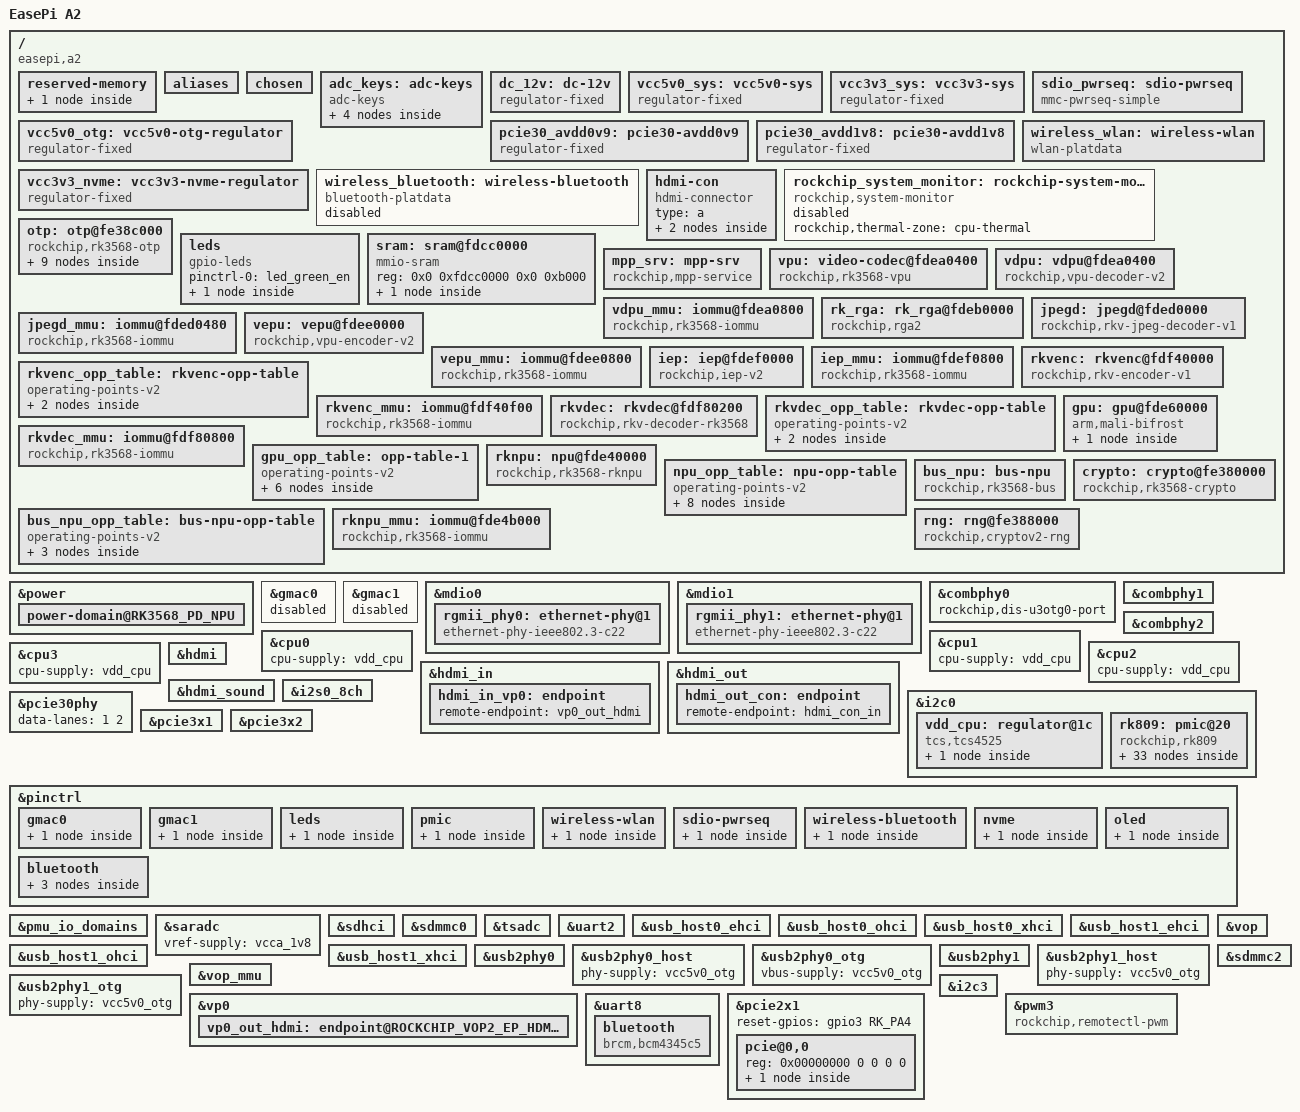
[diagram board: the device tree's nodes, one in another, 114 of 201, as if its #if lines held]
// SPDX-License-Identifier: GPL-2.0-or-later OR MIT
/*
 * Copyright (c) 2020 Rockchip Electronics Co., Ltd.
 * Copyright (c) 2021 Rockchip Electronics Co., Ltd.
 * Copyright (c) 2025 jjm2473 <jjm2473@gmail.com>
 */

/dts-v1/;
#include <dt-bindings/gpio/gpio.h>
#include <dt-bindings/input/input.h>
#include <dt-bindings/leds/common.h>
#include <dt-bindings/pinctrl/rockchip.h>
#include <dt-bindings/soc/rockchip,vop2.h>
#include "rk3568.dtsi"

/ {
	compatible = "easepi,a2", "rockchip,rk3568";
	model = "EasePi A2";
	kdebug = "0";
	hwmodel_id = "A2";
	hw_support = "hdmi";
	eth_order = "0000:01:00.0";

	reserved-memory {
		#address-cells = <2>;
		#size-cells = <2>;
		ranges;

		ramoops: ramoops@110000 {
			compatible = "ramoops";
			reg = <0 0x110000 0 0xf0000>;
			console-size = <0x80000>;
			ftrace-size = <0x00000>;
			pmsg-size = <0x50000>;
			record-size = <0x20000>;
		};
	};

	aliases {
		mmc0 = &sdmmc0;
		mmc1 = &sdhci;
		mmc2 = &sdmmc2;

		ethernet0 = &pcie_eth0;

		serial0 = &uart8;

		led-boot = &led_green;
		led-failsafe = &led_green;
		led-running = &led_green;
		led-upgrade = &led_green;
	};

	chosen {
		stdout-path = "serial2:1500000n8";
		power-key-factory-reset;
		power-key-dbclick;
	};

	adc_keys: adc-keys {
		compatible = "adc-keys";
		io-channels = <&saradc 0>;
		io-channel-names = "buttons";
		keyup-threshold-microvolt = <1800000>;
		poll-interval = <100>;

		vol-up-key {
		label = "volume up";
		linux,code = <KEY_VOLUMEUP>;
		press-threshold-microvolt = <175000>;
	};

		vol-down-key {
			label = "volume down";
			linux,code = <KEY_VOLUMEDOWN>;
			press-threshold-microvolt = <297500>;
		};

		menu-key {
			label = "menu";
			linux,code = <KEY_MENU>;
			press-threshold-microvolt = <980000>;
		};

		back-key {
			label = "back";
			linux,code = <KEY_BACK>;
			press-threshold-microvolt = <1305500>;
		};
	};

	dc_12v: dc-12v {
		compatible = "regulator-fixed";
		regulator-name = "dc_12v";
		regulator-always-on;
		regulator-boot-on;
		regulator-min-microvolt = <12000000>;
		regulator-max-microvolt = <12000000>;
	};
	vcc5v0_sys: vcc5v0-sys {
		compatible = "regulator-fixed";
		regulator-name = "vcc5v0_sys";
		regulator-always-on;
		regulator-boot-on;
		regulator-min-microvolt = <5000000>;
		regulator-max-microvolt = <5000000>;
		vin-supply = <&dc_12v>;
	};
	vcc3v3_sys: vcc3v3-sys {
		compatible = "regulator-fixed";
		regulator-name = "vcc3v3_sys";
		regulator-always-on;
		regulator-boot-on;
		regulator-min-microvolt = <3300000>;
		regulator-max-microvolt = <3300000>;
		vin-supply = <&dc_12v>;
	};
	vcc5v0_otg: vcc5v0-otg-regulator {
		compatible = "regulator-fixed";
		regulator-name = "vcc5v0_otg";
		regulator-always-on;
		regulator-boot-on;
		regulator-min-microvolt = <5000000>;
		regulator-max-microvolt = <5000000>;
		vin-supply = <&vcc5v0_sys>;
	};
	pcie30_avdd0v9: pcie30-avdd0v9 {
		compatible = "regulator-fixed";
		regulator-name = "pcie30_avdd0v9";
		regulator-always-on;
		regulator-boot-on;
		regulator-min-microvolt = <900000>;
		regulator-max-microvolt = <900000>;
		vin-supply = <&vcc3v3_sys>;
	};
	pcie30_avdd1v8: pcie30-avdd1v8 {
		compatible = "regulator-fixed";
		regulator-name = "pcie30_avdd1v8";
		regulator-always-on;
		regulator-boot-on;
		regulator-min-microvolt = <1800000>;
		regulator-max-microvolt = <1800000>;
		vin-supply = <&vcc3v3_sys>;
	};
	vcc3v3_nvme: vcc3v3-nvme-regulator {
		compatible = "regulator-fixed";
		regulator-name = "vcc3v3_nvme";
		regulator-min-microvolt = <3300000>;
		regulator-max-microvolt = <3300000>;
		enable-active-high;
		gpio = <&gpio0 RK_PA5 GPIO_ACTIVE_HIGH>;
		vin-supply = <&dc_12v>;
		pinctrl-names = "default";
		pinctrl-0 = <&vcc3v3_nvme_en>;
	};

	sdio_pwrseq: sdio-pwrseq {
		compatible = "mmc-pwrseq-simple";
		clocks = <&rk809 1>;
		clock-names = "ext_clock";
		pinctrl-names = "default";
		pinctrl-0 = <&wifi_enable_h>;
	};

	wireless_wlan: wireless-wlan {
		compatible = "wlan-platdata";
		rockchip,grf = <&grf>;
		wifi_chip_type = "ap6398s";
		WIFI,poweren_gpio = <&gpio3 RK_PD5 GPIO_ACTIVE_HIGH>;
		status = "okay";
	};

	wireless_bluetooth: wireless-bluetooth {
		compatible = "bluetooth-platdata";
		clocks = <&rk809 1>;
		clock-names = "ext_clock";
		uart_rts_gpios = <&gpio2 RK_PB1 GPIO_ACTIVE_LOW>;
		pinctrl-names = "default", "rts_gpio";
		pinctrl-0 = <&uart8m0_rtsn>;
		pinctrl-1 = <&uart8_gpios>;
		BT,reset_gpio    = <&gpio3 RK_PA0 GPIO_ACTIVE_HIGH>;
		BT,wake_gpio     = <&gpio3 RK_PA1 GPIO_ACTIVE_HIGH>;
		BT,wake_host_irq = <&gpio3 RK_PA2 GPIO_ACTIVE_HIGH>;
		status = "okay";
	};

	hdmi-con {
		compatible = "hdmi-connector";
		type = "a";

		port {
			hdmi_con_in: endpoint {
				remote-endpoint = <&hdmi_out_con>;
			};
		};
	};

	rockchip_system_monitor: rockchip-system-monitor {
		compatible = "rockchip,system-monitor";
		rockchip,thermal-zone = "cpu-thermal";
		status = "disabled";
	};

	otp: otp@fe38c000 {
		compatible = "rockchip,rk3568-otp";
		reg = <0x0 0xfe38c000 0x0 0x4000>;
		#address-cells = <1>;
		#size-cells = <1>;
		clocks = <&cru CLK_OTPC_NS_USR>, <&cru CLK_OTPC_NS_SBPI>,
				<&cru PCLK_OTPC_NS>, <&cru PCLK_OTPPHY>;
		clock-names = "usr", "sbpi", "apb", "phy";
		resets = <&cru SRST_OTPPHY>;
		reset-names = "otp_phy";

		specification_serial_number: specification-serial-number@7 {
			reg = <0x07 0x1>;
			bits = <0 5>;
		};
		mbist_vmin: mbist-vmin@9 {
			reg = <0x09 0x1>;
			bits = <0 4>;
		};
		log_leakage: log-leakage@1b {
			reg = <0x1b 0x1>;
		};
		core_pvtm: core-pvtm@2a {
			reg = <0x2a 0x2>;
		};
		remark_spec_serial_number: remark-spec-serial-number@56 {
			reg = <0x56 0x1>;
			bits = <0 5>;
		};
	};

	leds {
		compatible = "gpio-leds";
		pinctrl-names = "default";
		pinctrl-0 = <&led_green_en>;

		led_green: green {
			gpios = <&gpio2 RK_PD7 GPIO_ACTIVE_HIGH>;
			label = "green:sys";
			linux,default-trigger = "timer";
		};
	};

};

/* ===== Inline VPU support (from rk3568-vpu.dtsi) ===== */
/delete-node/ &vepu;

/ {
	sram: sram@fdcc0000 {
		compatible = "mmio-sram";
		reg = <0x0 0xfdcc0000 0x0 0xb000>;

		#address-cells = <1>;
		#size-cells = <1>;
		ranges = <0x0 0x0 0xfdcc0000 0xb000>;

		/* start address and size should be 4k algin */
		rkvdec_sram: rkvdec-sram@0 {
			reg = <0x0 0xb000>;
		};
	};

	mpp_srv: mpp-srv {
		compatible = "rockchip,mpp-service";
		rockchip,taskqueue-count = <6>;
		rockchip,resetgroup-count = <6>;
		status = "disabled";
	};

	vpu: video-codec@fdea0400 {
		compatible = "rockchip,rk3568-vpu";
		reg = <0x0 0xfdea0000 0x0 0x800>;
		interrupts = <GIC_SPI 139 IRQ_TYPE_LEVEL_HIGH>;
		clocks = <&cru ACLK_VPU>, <&cru HCLK_VPU>;
		clock-names = "aclk", "hclk";
		iommus = <&vdpu_mmu>;
		power-domains = <&power RK3568_PD_VPU>;
	};

	vdpu: vdpu@fdea0400 {
		compatible = "rockchip,vpu-decoder-v2";
		reg = <0x0 0xfdea0400 0x0 0x400>;
		interrupts = <GIC_SPI 139 IRQ_TYPE_LEVEL_HIGH>;
		interrupt-names = "irq_dec";
		clocks = <&cru ACLK_VPU>, <&cru HCLK_VPU>;
		clock-names = "aclk_vcodec", "hclk_vcodec";
		resets = <&cru SRST_A_VPU>, <&cru SRST_H_VPU>;
		reset-names = "video_a", "video_h";
		iommus = <&vdpu_mmu>;
		power-domains = <&power RK3568_PD_VPU>;
		rockchip,srv = <&mpp_srv>;
		rockchip,taskqueue-node = <0>;
		rockchip,resetgroup-node = <0>;
		status = "disabled";
	};

	vdpu_mmu: iommu@fdea0800 {
		compatible = "rockchip,rk3568-iommu", "rockchip,iommu-v2";
		reg = <0x0 0xfdea0800 0x0 0x40>;
		interrupts = <GIC_SPI 138 IRQ_TYPE_LEVEL_HIGH>;
		interrupt-names = "vdpu_mmu";
		clock-names = "aclk", "iface";
		clocks = <&cru ACLK_VPU>, <&cru HCLK_VPU>;
		power-domains = <&power RK3568_PD_VPU>;
		#iommu-cells = <0>;
		status = "disabled";
	};

	rk_rga: rk_rga@fdeb0000 {
		compatible = "rockchip,rga2";
		reg = <0x0 0xfdeb0000 0x0 0x1000>;
		interrupts = <GIC_SPI 90 IRQ_TYPE_LEVEL_HIGH>;
		clocks = <&cru ACLK_RGA>, <&cru HCLK_RGA>, <&cru CLK_RGA_CORE>;
		clock-names = "aclk_rga", "hclk_rga", "clk_rga";
		power-domains = <&power RK3568_PD_RGA>;
		status = "disabled";
	};

	jpegd: jpegd@fded0000 {
		compatible = "rockchip,rkv-jpeg-decoder-v1";
		reg = <0x0 0xfded0000 0x0 0x400>;
		interrupts = <GIC_SPI 62 IRQ_TYPE_LEVEL_HIGH>;
		clocks = <&cru ACLK_JDEC>, <&cru HCLK_JDEC>;
		clock-names = "aclk_vcodec", "hclk_vcodec";
		rockchip,disable-auto-freq;
		resets = <&cru SRST_A_JDEC>, <&cru SRST_H_JDEC>;
		reset-names = "video_a", "video_h";
		iommus = <&jpegd_mmu>;
		rockchip,srv = <&mpp_srv>;
		rockchip,taskqueue-node = <1>;
		rockchip,resetgroup-node = <1>;
		power-domains = <&power RK3568_PD_RGA>;
		status = "disabled";
	};

	jpegd_mmu: iommu@fded0480 {
		compatible = "rockchip,rk3568-iommu", "rockchip,iommu-v2";
		reg = <0x0 0xfded0480 0x0 0x40>;
		interrupts = <GIC_SPI 61 IRQ_TYPE_LEVEL_HIGH>;
		interrupt-names = "jpegd_mmu";
		clock-names = "aclk", "iface";
		clocks = <&cru ACLK_JDEC>, <&cru HCLK_JDEC>;
		power-domains = <&power RK3568_PD_RGA>;
		#iommu-cells = <0>;
		status = "disabled";
	};

	vepu: vepu@fdee0000 {
		compatible = "rockchip,vpu-encoder-v2";
		reg = <0x0 0xfdee0000 0x0 0x400>;
		interrupts = <GIC_SPI 64 IRQ_TYPE_LEVEL_HIGH>;
		clocks = <&cru ACLK_JENC>, <&cru HCLK_JENC>;
		clock-names = "aclk_vcodec", "hclk_vcodec";
		rockchip,disable-auto-freq;
		resets = <&cru SRST_A_JENC>, <&cru SRST_H_JENC>;
		reset-names = "video_a", "video_h";
		iommus = <&vepu_mmu>;
		rockchip,srv = <&mpp_srv>;
		rockchip,taskqueue-node = <2>;
		rockchip,resetgroup-node = <2>;
		power-domains = <&power RK3568_PD_RGA>;
		status = "disabled";
	};

	vepu_mmu: iommu@fdee0800 {
		compatible = "rockchip,rk3568-iommu", "rockchip,iommu-v2";
		reg = <0x0 0xfdee0800 0x0 0x40>;
		interrupts = <GIC_SPI 63 IRQ_TYPE_LEVEL_HIGH>;
		interrupt-names = "vepu_mmu";
		clocks = <&cru ACLK_JENC>, <&cru HCLK_JENC>;
		clock-names = "aclk", "iface";
		power-domains = <&power RK3568_PD_RGA>;
		#iommu-cells = <0>;
		status = "disabled";
	};

	iep: iep@fdef0000 {
		compatible = "rockchip,iep-v2";
		reg = <0x0 0xfdef0000 0x0 0x500>;
		interrupts = <GIC_SPI 56 IRQ_TYPE_LEVEL_HIGH>;
		clocks = <&cru ACLK_IEP>, <&cru HCLK_IEP>, <&cru CLK_IEP_CORE>;
		clock-names = "aclk", "hclk", "sclk";
		resets = <&cru SRST_A_IEP>, <&cru SRST_H_IEP>,
			<&cru SRST_IEP_CORE>;
		reset-names = "rst_a", "rst_h", "rst_s";
		power-domains = <&power RK3568_PD_RGA>;
		rockchip,srv = <&mpp_srv>;
		rockchip,taskqueue-node = <5>;
		rockchip,resetgroup-node = <5>;
		iommus = <&iep_mmu>;
		status = "disabled";
	};

	iep_mmu: iommu@fdef0800 {
		compatible = "rockchip,rk3568-iommu", "rockchip,iommu-v2";
		reg = <0x0 0xfdef0800 0x0 0x100>;
		interrupts = <GIC_SPI 56 IRQ_TYPE_LEVEL_HIGH>;
		interrupt-names = "iep_mmu";
		clocks = <&cru ACLK_IEP>, <&cru HCLK_IEP>;
		clock-names = "aclk", "iface";
		#iommu-cells = <0>;
		power-domains = <&power RK3568_PD_RGA>;
		status = "disabled";
	};

	rkvenc: rkvenc@fdf40000 {
		compatible = "rockchip,rkv-encoder-v1";
		reg = <0x0 0xfdf40000 0x0 0x400>;
		interrupts = <GIC_SPI 140 IRQ_TYPE_LEVEL_HIGH>;
		interrupt-names = "irq_enc";
		clocks = <&cru ACLK_RKVENC>, <&cru HCLK_RKVENC>,
			<&cru CLK_RKVENC_CORE>;
		clock-names = "aclk_vcodec", "hclk_vcodec", "clk_core";
		rockchip,normal-rates = <297000000>, <0>, <297000000>;
		resets = <&cru SRST_A_RKVENC>, <&cru SRST_H_RKVENC>,
			<&cru SRST_RKVENC_CORE>;
		reset-names = "video_a", "video_h", "video_core";
		assigned-clocks = <&cru ACLK_RKVENC>, <&cru CLK_RKVENC_CORE>;
		assigned-clock-rates = <297000000>, <297000000>;
		iommus = <&rkvenc_mmu>;
		node-name = "rkvenc";
		rockchip,srv = <&mpp_srv>;
		rockchip,taskqueue-node = <3>;
		rockchip,resetgroup-node = <3>;
		power-domains = <&power RK3568_PD_RKVENC>;
		status = "disabled";
	};

	rkvenc_opp_table: rkvenc-opp-table {
		compatible = "operating-points-v2";

		nvmem-cells = <&core_pvtm>;
		nvmem-cell-names = "pvtm";
		rockchip,pvtm-voltage-sel = <
			0        84000   0
			84001    91000   1
			91001    100000  2
		>;
		rockchip,pvtm-ch = <0 5>;

		opp-297000000 {
			opp-hz = /bits/ 64 <297000000>;
			opp-microvolt = <900000>;
			opp-microvolt-L0 = <900000>;
			opp-microvolt-L1 = <875000>;
			opp-microvolt-L2 = <875000>;
		};
		opp-400000000 {
			opp-hz = /bits/ 64 <400000000>;
			opp-microvolt = <950000>;
			opp-microvolt-L0 = <950000>;
			opp-microvolt-L1 = <925000>;
			opp-microvolt-L2 = <900000>;
		};
	};

	rkvenc_mmu: iommu@fdf40f00 {
		compatible = "rockchip,rk3568-iommu", "rockchip,iommu-v2";
		reg = <0x0 0xfdf40f00 0x0 0x40>, <0x0 0xfdf40f40 0x0 0x40>;
		interrupts = <GIC_SPI 141 IRQ_TYPE_LEVEL_HIGH>,
			<GIC_SPI 142 IRQ_TYPE_LEVEL_HIGH>;
		interrupt-names = "rkvenc_mmu0", "rkvenc_mmu1";
		clocks = <&cru ACLK_RKVENC>, <&cru HCLK_RKVENC>;
		clock-names = "aclk", "iface";
		rockchip,disable-mmu-reset;
		rockchip,enable-cmd-retry;
		#iommu-cells = <0>;
		power-domains = <&power RK3568_PD_RKVENC>;
		status = "disabled";
	};

	rkvdec: rkvdec@fdf80200 {
		compatible = "rockchip,rkv-decoder-rk3568", "rockchip,rkv-decoder-v2";
		reg = <0x0 0xfdf80200 0x0 0x400>, <0x0 0xfdf80100 0x0 0x100>;
		reg-names = "regs", "link";
		interrupts = <GIC_SPI 91 IRQ_TYPE_LEVEL_HIGH>;
		interrupt-names = "irq_dec";
		clocks = <&cru ACLK_RKVDEC>, <&cru HCLK_RKVDEC>,
			 <&cru CLK_RKVDEC_CA>, <&cru CLK_RKVDEC_CORE>,
			 <&cru CLK_RKVDEC_HEVC_CA>;
		clock-names = "aclk_vcodec", "hclk_vcodec","clk_cabac",
			      "clk_core", "clk_hevc_cabac";
		rockchip,normal-rates = <297000000>, <0>, <297000000>,
					<297000000>, <600000000>;
		rockchip,advanced-rates = <396000000>, <0>, <396000000>,
					<396000000>, <600000000>;
		rockchip,default-max-load = <2088960>;
		resets = <&cru SRST_A_RKVDEC>, <&cru SRST_H_RKVDEC>,
			 <&cru SRST_RKVDEC_CA>, <&cru SRST_RKVDEC_CORE>,
			 <&cru SRST_RKVDEC_HEVC_CA>;
		assigned-clocks = <&cru ACLK_RKVDEC>, <&cru CLK_RKVDEC_CA>,
				  <&cru CLK_RKVDEC_CORE>, <&cru CLK_RKVDEC_HEVC_CA>;
		assigned-clock-rates = <297000000>, <297000000>, <297000000>, <297000000>;
		reset-names = "video_a", "video_h", "video_cabac",
			      "video_core", "video_hevc_cabac";
		power-domains = <&power RK3568_PD_RKVDEC>;
		vdec-supply = <&vdd_logic>;
		iommus = <&rkvdec_mmu>;
		rockchip,srv = <&mpp_srv>;
		rockchip,taskqueue-node = <4>;
		rockchip,resetgroup-node = <4>;
		rockchip,sram = <&rkvdec_sram>;
		/* rcb_iova: start and size */
		rockchip,rcb-iova = <0x10000000 65536>;
		rockchip,rcb-min-width = <512>;
		rockchip,task-capacity = <16>;
		status = "disabled";
	};

	rkvdec_opp_table: rkvdec-opp-table {
		compatible = "operating-points-v2";

		nvmem-cells = <&log_leakage>, <&core_pvtm>;
		nvmem-cell-names = "leakage", "pvtm";
		rockchip,leakage-voltage-sel = <
			1   80    0
			81  254   1
		>;
		rockchip,pvtm-voltage-sel = <
			0        84000   0
			84001    100000  1
		>;
		rockchip,pvtm-ch = <0 5>;

		opp-297000000 {
			opp-hz = /bits/ 64 <297000000>;
			opp-microvolt = <900000>;
			opp-microvolt-L0 = <900000>;
			opp-microvolt-L1 = <875000>;
		};
		opp-400000000 {
			opp-hz = /bits/ 64 <400000000>;
			opp-microvolt = <900000>;
		};
	};

	rkvdec_mmu: iommu@fdf80800 {
		compatible = "rockchip,rk3568-iommu", "rockchip,iommu-v2";
		reg = <0x0 0xfdf80800 0x0 0x40>, <0x0 0xfdf80840 0x0 0x40>;
		interrupts = <GIC_SPI 92 IRQ_TYPE_LEVEL_HIGH>;
		interrupt-names = "rkvdec_mmu";
		clocks = <&cru ACLK_RKVDEC>, <&cru HCLK_RKVDEC>;
		clock-names = "aclk", "iface";
		power-domains = <&power RK3568_PD_RKVDEC>;
		#iommu-cells = <0>;
		status = "disabled";
	};

};

&iep {
	status = "okay";
};

&iep_mmu {
	status = "okay";
};

&jpegd {
	status = "okay";
};

&jpegd_mmu {
	status = "okay";
};

&mpp_srv {
	status = "okay";
};

&rk_rga {
	status = "okay";
};

&rkvdec {
	rockchip,disable-auto-freq;
	assigned-clock-rates = <396000000>, <396000000>, <396000000>, <600000000>;
	status = "okay";
};

&rkvdec_mmu {
	status = "okay";
};

&rkvenc {
	status = "okay";
};

&rkvenc_mmu {
	status = "okay";
};

&vdpu {
	status = "okay";
};

&vdpu_mmu {
	status = "okay";
};

&vepu {
	status = "okay";
};

&vepu_mmu {
	status = "okay";
};

/* ===== Inline GPU support (from rk3568-gpu.dtsi) ===== */
&otp {
	gpu_leakage: gpu-leakage@1d {
		reg = <0x1d 0x1>;
	};
	gpu_opp_info: gpu-opp-info@3c {
		reg = <0x3c 0x6>;
	};
};

/ {

	gpu_opp_table: opp-table-1 {
		compatible = "operating-points-v2";

		mbist-vmin = <825000 900000 950000>;
		nvmem-cells = <&gpu_leakage>, <&core_pvtm>, <&mbist_vmin>, <&gpu_opp_info>,
			      <&specification_serial_number>, <&remark_spec_serial_number>;
		nvmem-cell-names = "leakage", "pvtm", "mbist-vmin", "opp-info",
				   "specification_serial_number", "remark_spec_serial_number";
		rockchip,supported-hw;
		rockchip,max-volt = <1000000>;
		rockchip,temp-hysteresis = <5000>;
		rockchip,low-temp = <0>;
		rockchip,low-temp-adjust-volt = <
			/* MHz    MHz    uV */
			   0      800    50000
		>;
		rockchip,pvtm-voltage-sel = <
			0        84000   0
			84001    87000   1
			87001    91000   2
			91001    100000  3
		>;
		rockchip,pvtm-ch = <0 5>;

		/* RK3568 && RK3568M gpu OPPs */
		opp-200000000 {
			opp-supported-hw = <0xfb 0xffff>;
			opp-hz = /bits/ 64 <200000000>;
			opp-microvolt = <850000 850000 1000000>;
		};

		opp-300000000 {
			opp-supported-hw = <0xfb 0xffff>;
			opp-hz = /bits/ 64 <300000000>;
			opp-microvolt = <850000 850000 1000000>;
		};

		opp-400000000 {
			opp-supported-hw = <0xfb 0xffff>;
			opp-hz = /bits/ 64 <400000000>;
			opp-microvolt = <850000 850000 1000000>;
		};

		opp-600000000 {
			opp-supported-hw = <0xfb 0xffff>;
			opp-hz = /bits/ 64 <600000000>;
			opp-microvolt = <900000 900000 1000000>;
			opp-microvolt-L0 = <900000 900000 1000000>;
			opp-microvolt-L1 = <875000 875000 1000000>;
			opp-microvolt-L2 = <850000 850000 1000000>;
			opp-microvolt-L3 = <850000 850000 1000000>;
		};

		opp-700000000 {
			opp-supported-hw = <0xfb 0xffff>;
			opp-hz = /bits/ 64 <700000000>;
			opp-microvolt = <950000 950000 1000000>;
			opp-microvolt-L0 = <950000 950000 1000000>;
			opp-microvolt-L1 = <925000 925000 1000000>;
			opp-microvolt-L2 = <900000 900000 1000000>;
			opp-microvolt-L3 = <875000 875000 1000000>;
		};

		opp-800000000 {
			opp-supported-hw = <0xf9 0xffff>;
			opp-hz = /bits/ 64 <800000000>;
			opp-microvolt = <1000000 1000000 1000000>;
			opp-microvolt-L0 = <1000000 1000000 1000000>;
			opp-microvolt-L1 = <975000 975000 1000000>;
			opp-microvolt-L2 = <950000 950000 1000000>;
			opp-microvolt-L3 = <925000 925000 1000000>;
		};
	};

	gpu: gpu@fde60000 {
		compatible = "arm,mali-bifrost";
		reg = <0x0 0xfde60000 0x0 0x4000>;

		interrupts = <GIC_SPI 39 IRQ_TYPE_LEVEL_HIGH>,
			     <GIC_SPI 41 IRQ_TYPE_LEVEL_HIGH>,
			     <GIC_SPI 40 IRQ_TYPE_LEVEL_HIGH>;
		interrupt-names = "gpu", "mmu", "job";

		upthreshold = <40>;
		downdifferential = <10>;

		clocks = <&scmi_clk 1>, <&cru CLK_GPU>;
		clock-names = "gpu", "bus";
		power-domains = <&power RK3568_PD_GPU>;
		#cooling-cells = <2>;
		operating-points-v2 = <&gpu_opp_table>;

		status = "disabled";
		gpu_power_model: power-model {
			compatible = "simple-power-model";
			leakage-range= <5 15>;
			ls = <(-24002) 22823 0>;
			static-coefficient = <100000>;
			dynamic-coefficient = <953>;
			ts = <(-108890) 63610 (-1355) 20>;
			thermal-zone = "gpu-thermal";
		};
	};

};

/* ===== Inline NPU support (from rk3568-npu.dtsi) ===== */
&otp {
	npu_leakage: npu-leakage@1c {
		reg = <0x1c 0x1>;
	};
	npu_opp_info: npu-opp-info@42 {
		reg = <0x42 0x6>;
	};
};

&power {
	// vcc-supply = <&vdd_npu>;
	// These power domains are grouped by VD_NPU
	power-domain@RK3568_PD_NPU {
		reg = <RK3568_PD_NPU>;
		clocks = <&cru ACLK_NPU_PRE>,
				<&cru HCLK_NPU_PRE>,
				<&cru PCLK_NPU_PRE>;
		pm_qos = <&qos_npu>;
		#power-domain-cells = <0>;
	};
};

/ {

	rknpu: npu@fde40000 {
		compatible = "rockchip,rk3568-rknpu", "rockchip,rknpu";
		reg = <0x0 0xfde40000 0x0 0x10000>;
		interrupts = <GIC_SPI 151 IRQ_TYPE_LEVEL_HIGH>;
		clocks = <&scmi_clk 2>, <&cru CLK_NPU>, <&cru ACLK_NPU>, <&cru HCLK_NPU>;
		clock-names = "scmi_clk", "clk", "aclk", "hclk";
		assigned-clocks = <&cru CLK_NPU>;
		assigned-clock-rates = <600000000>;
		resets = <&cru SRST_A_NPU>, <&cru SRST_H_NPU>;
		reset-names = "srst_a", "srst_h";
		power-domains = <&power RK3568_PD_NPU>;
		operating-points-v2 = <&npu_opp_table>;
		iommus = <&rknpu_mmu>;
		status = "disabled";
	};

	npu_opp_table: npu-opp-table {
		compatible = "operating-points-v2";

		mbist-vmin = <825000 900000 950000>;
		nvmem-cells = <&npu_leakage>, <&core_pvtm>, <&mbist_vmin>, <&npu_opp_info>,
			      <&specification_serial_number>, <&remark_spec_serial_number>;
		nvmem-cell-names = "leakage", "pvtm", "mbist-vmin", "opp-info",
				   "specification_serial_number", "remark_spec_serial_number";
		rockchip,supported-hw;
		rockchip,max-volt = <1000000>;
		rockchip,temp-hysteresis = <5000>;
		rockchip,low-temp = <0>;
		rockchip,low-temp-adjust-volt = <
			/* MHz    MHz    uV */
			   0      1000    50000
		>;
		rockchip,pvtm-voltage-sel = <
			0        84000   0
			84001    87000   1
			87001    91000   2
			91001    100000  3
		>;
		rockchip,pvtm-ch = <0 5>;
		rockchip,init-freq = <900000>;

		/* RK3568 && RK3568M npu OPPs */
		opp-200000000 {
			opp-supported-hw = <0xfb 0xffff>;
			opp-hz = /bits/ 64 <200000000>;
			opp-microvolt = <850000 850000 1000000>;
		};
		opp-300000000 {
			opp-supported-hw = <0xfb 0xffff>;
			opp-hz = /bits/ 64 <297000000>;
			opp-microvolt = <850000 850000 1000000>;
		};
		opp-400000000 {
			opp-supported-hw = <0xfb 0xffff>;
			opp-hz = /bits/ 64 <400000000>;
			opp-microvolt = <850000 850000 1000000>;
		};
		opp-600000000 {
			opp-supported-hw = <0xfb 0xffff>;
			opp-hz = /bits/ 64 <600000000>;
			opp-microvolt = <850000 850000 1000000>;
		};
		opp-700000000 {
			opp-supported-hw = <0xfb 0xffff>;
			opp-hz = /bits/ 64 <700000000>;
			opp-microvolt = <875000 875000 1000000>;
			opp-microvolt-L0 = <875000 875000 1000000>;
			opp-microvolt-L1 = <850000 850000 1000000>;
			opp-microvolt-L2 = <850000 850000 1000000>;
			opp-microvolt-L3 = <850000 850000 1000000>;
		};
		opp-800000000 {
			opp-supported-hw = <0xfb 0xffff>;
			opp-hz = /bits/ 64 <800000000>;
			opp-microvolt = <925000 925000 1000000>;
			opp-microvolt-L0 = <925000 925000 1000000>;
			opp-microvolt-L1 = <900000 900000 1000000>;
			opp-microvolt-L2 = <875000 875000 1000000>;
			opp-microvolt-L3 = <875000 875000 1000000>;
		};
		opp-900000000 {
			opp-supported-hw = <0xf9 0xffff>;
			opp-hz = /bits/ 64 <900000000>;
			opp-microvolt = <975000 975000 1000000>;
			opp-microvolt-L0 = <975000 975000 1000000>;
			opp-microvolt-L1 = <950000 950000 1000000>;
			opp-microvolt-L2 = <925000 925000 1000000>;
			opp-microvolt-L3 = <900000 900000 1000000>;
		};
		opp-1000000000 {
			opp-supported-hw = <0xf9 0xffff>;
			opp-hz = /bits/ 64 <1000000000>;
			opp-microvolt = <1000000 1000000 1000000>;
			opp-microvolt-L0 = <1000000 1000000 1000000>;
			opp-microvolt-L1 = <975000 975000 1000000>;
			opp-microvolt-L2 = <950000 950000 1000000>;
			opp-microvolt-L3 = <925000 925000 1000000>;
			status = "disabled";
		};
	};

	bus_npu: bus-npu {
		compatible = "rockchip,rk3568-bus";
		rockchip,busfreq-policy = "clkfreq";
		clocks = <&scmi_clk 2>;
		clock-names = "bus";
		operating-points-v2 = <&bus_npu_opp_table>;
		status = "disabled";
	};

	bus_npu_opp_table: bus-npu-opp-table {
		compatible = "operating-points-v2";
		opp-shared;

		nvmem-cells = <&core_pvtm>;
		nvmem-cell-names = "pvtm";
		rockchip,pvtm-voltage-sel = <
			0        84000   0
			84001    91000   1
			91001    100000  2
		>;
		rockchip,pvtm-ch = <0 5>;

		opp-700000000 {
			opp-hz = /bits/ 64 <700000000>;
			opp-microvolt = <900000>;
			opp-microvolt-L0 = <900000>;
			opp-microvolt-L1 = <875000>;
			opp-microvolt-L2 = <875000>;
		};
		opp-900000000 {
			opp-hz = /bits/ 64 <900000000>;
			opp-microvolt = <900000>;
		};
		opp-1000000000 {
			opp-hz = /bits/ 64 <1000000000>;
			opp-microvolt = <950000>;
			opp-microvolt-L0 = <950000>;
			opp-microvolt-L1 = <925000>;
			opp-microvolt-L2 = <900000>;
		};
	};

	rknpu_mmu: iommu@fde4b000 {
		compatible = "rockchip,rk3568-iommu", "rockchip,iommu-v2";
		reg = <0x0 0xfde4b000 0x0 0x40>;
		interrupts = <GIC_SPI 151 IRQ_TYPE_LEVEL_HIGH>;
		interrupt-names = "rknpu_mmu";
		clocks = <&cru ACLK_NPU>, <&cru HCLK_NPU>;
		clock-names = "aclk", "iface";
		power-domains = <&power RK3568_PD_NPU>;
		#iommu-cells = <0>;
		status = "disabled";
	};

};

/* ===== Inline Crypto support (from rk3568-crypto.dtsi) ===== */
/ {

	crypto: crypto@fe380000 {
		compatible = "rockchip,rk3568-crypto";
		reg = <0x0 0xfe380000 0x0 0x4000>;
		interrupts = <GIC_SPI 4 IRQ_TYPE_LEVEL_HIGH>;
		clocks = <&cru ACLK_CRYPTO_NS>, <&cru HCLK_CRYPTO_NS>,
			<&cru CLK_CRYPTO_NS_CORE>, <&cru CLK_CRYPTO_NS_PKA>;
		clock-names = "aclk", "hclk", "sclk", "apb_pclk";
		assigned-clocks = <&cru CLK_CRYPTO_NS_CORE>;
		assigned-clock-rates = <200000000>;
		resets = <&cru SRST_CRYPTO_NS_CORE>;
		reset-names = "crypto-rst";
		status = "disabled";
	};

	rng: rng@fe388000 {
		compatible = "rockchip,cryptov2-rng", "rockchip,rk3568-rng";
		reg = <0x0 0xfe388000 0x0 0x2000>;
		clocks = <&cru CLK_TRNG_NS>, <&cru HCLK_TRNG_NS>;
		clock-names = "clk_trng", "hclk_trng";
		resets = <&cru SRST_TRNG_NS>;
		reset-names = "reset";
		status = "disabled";
	};

};

&crypto {
	status = "okay";
};

&rng {
	status = "okay";
};


/* ===== Carrier board (roc-k40pro) overrides ===== */

&gmac0 {
	phy-mode = "rgmii";
	clock_in_out = "input";

	snps,reset-gpio = <&gpio2 RK_PD3 GPIO_ACTIVE_LOW>;
	snps,reset-active-low;
	/* Reset time is 15ms, 50ms for rtl8211f */
	snps,reset-delays-us = <0 15000 50000>;

	assigned-clocks = <&cru SCLK_GMAC0_RX_TX>, <&cru SCLK_GMAC0>;
	assigned-clock-parents = <&cru SCLK_GMAC0_RGMII_SPEED>;
	assigned-clock-rates = <0>, <125000000>;
	phy-handle = <&rgmii_phy0>;
	pinctrl-names = "default";
	pinctrl-0 = <&gmac0_miim
		     &gmac0_tx_bus2
		     &gmac0_rx_bus2
		     &gmac0_rgmii_clk
		     &gmac0_rgmii_bus>;

	tx_delay = <0x3c>;
	rx_delay = <0x2f>;

	status = "okay";
};

&gmac1 {
	phy-mode = "rgmii";
	clock_in_out = "input";

	snps,reset-gpio = <&gpio2 RK_PD1 GPIO_ACTIVE_LOW>;
	snps,reset-active-low;
	/* Reset time is 15ms, 50ms for rtl8211f */
	snps,reset-delays-us = <0 15000 50000>;

	assigned-clocks = <&cru SCLK_GMAC1_RX_TX>, <&cru SCLK_GMAC1>;
	assigned-clock-parents = <&cru SCLK_GMAC1_RGMII_SPEED>;
	assigned-clock-rates = <0>, <125000000>;
	phy-handle = <&rgmii_phy1>;
	pinctrl-names = "default";
	pinctrl-0 = <&gmac1m1_miim
		     &gmac1m1_tx_bus2
		     &gmac1m1_rx_bus2
		     &gmac1m1_rgmii_clk
		     &gmac1m1_rgmii_bus>;

	tx_delay = <0x4f>;
	rx_delay = <0x26>;

	status = "okay";
};

&mdio0 {
	rgmii_phy0: ethernet-phy@1 {
		compatible = "ethernet-phy-ieee802.3-c22";
		reg = <0x1>;
		pinctrl-0 = <&eth_phy0_reset_pin>;
		pinctrl-names = "default";
		realtek,led-data = <0xAC10>;
	};
};

&mdio1 {
	rgmii_phy1: ethernet-phy@1 {
		compatible = "ethernet-phy-ieee802.3-c22";
		reg = <0x1>;
		pinctrl-0 = <&eth_phy1_reset_pin>;
		pinctrl-names = "default";
		realtek,led-data = <0xAC10>;
	};
};

&combphy0 {
	rockchip,dis-u3otg0-port; /* disable USB3.0 */
	status = "okay";
};

&combphy1 {
	status = "okay";
};

&combphy2 {
	status = "okay";
};

&cpu0 {
	cpu-supply = <&vdd_cpu>;
};

&cpu1 {
	cpu-supply = <&vdd_cpu>;
};

&cpu2 {
	cpu-supply = <&vdd_cpu>;
};

&cpu3 {
	cpu-supply = <&vdd_cpu>;
};

&gpu {
	power-off-delay-ms = <200>;
	mali-supply = <&vdd_gpu>;
	status = "okay";
};

&hdmi {
	avdd-0v9-supply = <&vdda0v9_image>;
	avdd-1v8-supply = <&vcca1v8_image>;
	status = "okay";
};

&hdmi_in {
	hdmi_in_vp0: endpoint {
		remote-endpoint = <&vp0_out_hdmi>;
	};
};

&hdmi_out {
	hdmi_out_con: endpoint {
		remote-endpoint = <&hdmi_con_in>;
	};
};

&hdmi_sound {
	status = "okay";
};

&i2c0 {
	status = "okay";

	vdd_cpu: regulator@1c {
		compatible = "tcs,tcs4525";
		reg = <0x1c>;
		fcs,suspend-voltage-selector = <1>;
		regulator-name = "vdd_cpu";
		regulator-always-on;
		regulator-boot-on;
		regulator-min-microvolt = <800000>;
		regulator-max-microvolt = <1150000>;
		regulator-ramp-delay = <2300>;
		vin-supply = <&vcc5v0_sys>;

		regulator-state-mem {
			regulator-off-in-suspend;
		};
	};

	rk809: pmic@20 {
		compatible = "rockchip,rk809";
		reg = <0x20>;
		interrupt-parent = <&gpio0>;
		interrupts = <RK_PA3 IRQ_TYPE_LEVEL_LOW>;
		#clock-cells = <1>;
		pinctrl-names = "default";
		pinctrl-0 = <&pmic_int>;
		rockchip,system-power-controller;
		vcc1-supply = <&vcc3v3_sys>;
		vcc2-supply = <&vcc3v3_sys>;
		vcc3-supply = <&vcc3v3_sys>;
		vcc4-supply = <&vcc3v3_sys>;
		vcc5-supply = <&vcc3v3_sys>;
		vcc6-supply = <&vcc3v3_sys>;
		vcc7-supply = <&vcc3v3_sys>;
		vcc8-supply = <&vcc3v3_sys>;
		vcc9-supply = <&vcc3v3_sys>;
		wakeup-source;
		long-press-off-time-sec = <10>;

		regulators {
			vdd_logic: DCDC_REG1 {
				regulator-name = "vdd_logic";
				regulator-always-on;
				regulator-boot-on;
				regulator-initial-mode = <0x2>;
				regulator-min-microvolt = <500000>;
				regulator-max-microvolt = <1350000>;
				regulator-ramp-delay = <6001>;

				regulator-state-mem {
					regulator-off-in-suspend;
				};
			};

			vdd_gpu: DCDC_REG2 {
				regulator-name = "vdd_gpu";
				regulator-always-on;
				regulator-initial-mode = <0x2>;
				regulator-min-microvolt = <500000>;
				regulator-max-microvolt = <1350000>;
				regulator-ramp-delay = <6001>;

				regulator-state-mem {
					regulator-off-in-suspend;
				};
			};

			vcc_ddr: DCDC_REG3 {
				regulator-name = "vcc_ddr";
				regulator-always-on;
				regulator-boot-on;
				regulator-initial-mode = <0x2>;

				regulator-state-mem {
					regulator-on-in-suspend;
				};
			};

			vdd_npu: DCDC_REG4 {
				regulator-name = "vdd_npu";
				regulator-initial-mode = <0x2>;
				regulator-min-microvolt = <500000>;
				regulator-max-microvolt = <1350000>;
				regulator-ramp-delay = <6001>;

				regulator-state-mem {
					regulator-off-in-suspend;
				};
			};

			vcc_1v8: DCDC_REG5 {
				regulator-name = "vcc_1v8";
				regulator-always-on;
				regulator-boot-on;
				regulator-min-microvolt = <1800000>;
				regulator-max-microvolt = <1800000>;

				regulator-state-mem {
					regulator-off-in-suspend;
				};
			};

			vdda0v9_image: LDO_REG1 {
				regulator-name = "vdda0v9_image";
				regulator-min-microvolt = <950000>;
				regulator-max-microvolt = <950000>;

				regulator-state-mem {
					regulator-off-in-suspend;
				};
			};

			vdda_0v9: LDO_REG2 {
				regulator-name = "vdda_0v9";
				regulator-always-on;
				regulator-boot-on;
				regulator-min-microvolt = <900000>;
				regulator-max-microvolt = <900000>;

				regulator-state-mem {
					regulator-off-in-suspend;
				};
			};

			vdda0v9_pmu: LDO_REG3 {
				regulator-name = "vdda0v9_pmu";
				regulator-always-on;
				regulator-boot-on;
				regulator-min-microvolt = <900000>;
				regulator-max-microvolt = <900000>;

				regulator-state-mem {
					regulator-on-in-suspend;
					regulator-suspend-microvolt = <900000>;
				};
			};

			vccio_acodec: LDO_REG4 {
				regulator-name = "vccio_acodec";
				regulator-min-microvolt = <3300000>;
				regulator-max-microvolt = <3300000>;

				regulator-state-mem {
					regulator-off-in-suspend;
				};
			};

			vccio_sd: LDO_REG5 {
				regulator-name = "vccio_sd";
				regulator-min-microvolt = <1800000>;
				regulator-max-microvolt = <3300000>;

				regulator-state-mem {
					regulator-off-in-suspend;
				};
			};

			vcc3v3_pmu: LDO_REG6 {
				regulator-name = "vcc3v3_pmu";
				regulator-always-on;
				regulator-boot-on;
				regulator-min-microvolt = <3300000>;
				regulator-max-microvolt = <3300000>;

				regulator-state-mem {
					regulator-on-in-suspend;
					regulator-suspend-microvolt = <3300000>;
				};
			};

			vcca_1v8: LDO_REG7 {
				regulator-name = "vcca_1v8";
				regulator-always-on;
				regulator-boot-on;
				regulator-min-microvolt = <1800000>;
				regulator-max-microvolt = <1800000>;

				regulator-state-mem {
					regulator-off-in-suspend;
				};
			};

			vcca1v8_pmu: LDO_REG8 {
				regulator-name = "vcca1v8_pmu";
				regulator-always-on;
				regulator-boot-on;
				regulator-min-microvolt = <1800000>;
				regulator-max-microvolt = <1800000>;

				regulator-state-mem {
					regulator-on-in-suspend;
					regulator-suspend-microvolt = <1800000>;
				};
			};

			vcca1v8_image: LDO_REG9 {
				regulator-name = "vcca1v8_image";
				regulator-min-microvolt = <1800000>;
				regulator-max-microvolt = <1800000>;

				regulator-state-mem {
					regulator-off-in-suspend;
				};
			};

			vcc_3v3: SWITCH_REG1 {
				regulator-name = "vcc_3v3";
				regulator-always-on;
				regulator-boot-on;

				regulator-state-mem {
					regulator-off-in-suspend;
				};
			};

			vcc3v3_sd: SWITCH_REG2 {
				regulator-name = "vcc3v3_sd";
				regulator-always-on;
				regulator-boot-on;

				regulator-state-mem {
					regulator-off-in-suspend;
				};
			};
		};

	};
};

&i2s0_8ch {
	status = "okay";
};

&pcie30phy {
	data-lanes = <1 2>;
	status = "okay";
};

&pcie3x1 {
	num-lanes = <1>;
	status = "okay";
};

&pcie3x2 {
	num-lanes = <1>;
	status = "okay";
};

&pinctrl {
	gmac0 {
		eth_phy0_reset_pin: eth-phy0-reset-pin {
			rockchip,pins = <2 RK_PD3 RK_FUNC_GPIO &pcfg_pull_up>;
		};
	};

	gmac1 {
		eth_phy1_reset_pin: eth-phy1-reset-pin {
			rockchip,pins = <2 RK_PD1 RK_FUNC_GPIO &pcfg_pull_up>;
		};
	};

	leds {
		led_green_en: led-green-en {
			rockchip,pins =
				<2 RK_PD7 RK_FUNC_GPIO &pcfg_pull_none>;
		};
	};
	pmic {
		pmic_int: pmic-int {
			rockchip,pins = <0 RK_PA3 RK_FUNC_GPIO &pcfg_pull_up>;
		};
	};


	wireless-wlan {
		wifi_host_wake_irq: wifi-host-wake-irq {
			rockchip,pins = <3 RK_PD4 RK_FUNC_GPIO &pcfg_pull_down>;
		};
	};

	sdio-pwrseq {
		wifi_enable_h: wifi-enable-h {
			rockchip,pins = <3 RK_PD5 RK_FUNC_GPIO &pcfg_pull_none>;
		};
	};
	wireless-bluetooth {
		uart8_gpios: uart8-gpios {
			rockchip,pins = <2 RK_PB1 RK_FUNC_GPIO &pcfg_pull_none>;
		};
	};

};

&pmu_io_domains {
	pmuio1-supply = <&vcc3v3_pmu>;
	pmuio2-supply = <&vcc3v3_pmu>;
	vccio1-supply = <&vccio_acodec>;
	vccio3-supply = <&vccio_sd>;
	vccio4-supply = <&vcc_1v8>;
	vccio5-supply = <&vcc_3v3>;
	vccio6-supply = <&vcc_1v8>;
	vccio7-supply = <&vcc_3v3>;
	status = "okay";
};

&saradc {
	vref-supply = <&vcca_1v8>;
	status = "okay";
};

&sdhci {
	bus-width = <8>;
	max-frequency = <200000000>;
	non-removable;
	pinctrl-names = "default";
	pinctrl-0 = <&emmc_bus8 &emmc_clk &emmc_cmd>;
	status = "okay";
};

&sdmmc0 {
	max-frequency = <150000000>;
	no-sdio;
	no-mmc;
	bus-width = <4>;
	cap-mmc-highspeed;
	cap-sd-highspeed;
	disable-wp;
	vmmc-supply = <&vcc3v3_sd>;
	vqmmc-supply = <&vccio_sd>;
	pinctrl-names = "default";
	pinctrl-0 = <&sdmmc0_bus4 &sdmmc0_clk &sdmmc0_cmd &sdmmc0_det>;
	status = "okay";
};

&tsadc {
	rockchip,hw-tshut-mode = <1>;
	rockchip,hw-tshut-polarity = <0>;
	status = "okay";
};

&uart2 {
	status = "okay";
};

&usb_host0_ehci {
	status = "okay";
};

&usb_host0_ohci {
	status = "okay";
};

/* OTG Only USB2.0, Only device mode */
&usb_host0_xhci {
	phys = <&usb2phy0_otg>;
	phy-names = "usb2-phy";
	extcon = <&usb2phy0>;
	maximum-speed = "high-speed";
	dr_mode = "peripheral";
	status = "okay";
};

&usb_host1_ehci {
	status = "okay";
};

&usb_host1_ohci {
	status = "okay";
};

&usb_host1_xhci {
	status = "okay";
};

&usb2phy0 {
	status = "okay";
};

&usb2phy0_host {
	phy-supply = <&vcc5v0_otg>;
	status = "okay";
};

&usb2phy0_otg {
	vbus-supply = <&vcc5v0_otg>;
	status = "okay";
};

&usb2phy1 {
	status = "okay";
};

&usb2phy1_host {
	phy-supply = <&vcc5v0_otg>;
	status = "okay";
};

&usb2phy1_otg {
	phy-supply = <&vcc5v0_otg>;
	status = "okay";
};

&vop {
	assigned-clocks = <&cru DCLK_VOP0>, <&cru DCLK_VOP1>;
	assigned-clock-parents = <&pmucru PLL_HPLL>, <&cru PLL_VPLL>;
	status = "okay";
};

&vop_mmu {
	status = "okay";
};

&vp0 {
	vp0_out_hdmi: endpoint@ROCKCHIP_VOP2_EP_HDMI0 {
		reg = <ROCKCHIP_VOP2_EP_HDMI0>;
		remote-endpoint = <&hdmi_in_vp0>;
	};
};

/* ===== Rockchip IP overrides ===== */

#ifdef DT_ENABLE_NPU
&vdd_npu {
	regulator-init-microvolt = <900000>;
	regulator-always-on;
	regulator-boot-on;
};
#endif

&bus_npu {
	bus-supply = <&vdd_logic>;
	pvtm-supply = <&vdd_cpu>;
#ifdef DT_ENABLE_NPU
	status = "okay";
#endif
};

&rknpu {
	rknpu-supply = <&vdd_npu>;
#ifdef DT_ENABLE_NPU
	status = "okay";
#endif
};

&rknpu_mmu {
#ifdef DT_ENABLE_NPU
	status = "okay";
#endif
};


&rkvenc {
	venc-supply = <&vdd_logic>;
	status = "okay";
};

/* ===== EasePi A2 board-specific overrides ===== */

&gmac0 {
	status = "disabled";
};

&gmac1 {
	status = "disabled";
};

// Configure WL_REG_ON pin
&sdio_pwrseq {
	status = "okay";
	reset-gpios = <&gpio3 RK_PD5 GPIO_ACTIVE_LOW>;
	post-power-on-delay-ms = <200>;
};

// Configure WL_HOST_WAKE pin, required for OOB mode
&wireless_wlan {
	pinctrl-names = "default";
	pinctrl-0 = <&wifi_host_wake_irq>;
	WIFI,host_wake_irq = <&gpio3 RK_PD4 GPIO_ACTIVE_HIGH>;
	wifi_chip_type = "ap6255";
	status = "okay";
};

// bluetooth - mainline kernel serdev on uart8 (GPIO2 pins = hardware connection)
&uart8 {
	status = "okay";
	pinctrl-names = "default";
	pinctrl-0 = <&uart8m0_xfer &uart8m0_ctsn &uart8m0_rtsn>;
	uart-has-rtscts;

	bluetooth {
		compatible = "brcm,bcm4345c5";
		clocks = <&rk809 1>;
		clock-names = "ext_clock";
		host-wakeup-gpios = <&gpio0 RK_PD4 GPIO_ACTIVE_HIGH>;
		device-wakeup-gpios = <&gpio0 RK_PD5 GPIO_ACTIVE_HIGH>;
		shutdown-gpios = <&gpio4 RK_PC4 GPIO_ACTIVE_HIGH>;
		max-speed = <1500000>;
		pinctrl-names = "default";
		pinctrl-0 = <&bt_host_wake_gpio &bt_device_wake_gpio &bt_shutdown_gpio>;
		vbat-supply = <&vcc_3v3>;
		vddio-supply = <&vcc_1v8>;
	};
};

// wifi
&sdmmc2 {
	max-frequency = <150000000>;
	supports-sdio;
	bus-width = <4>;
	disable-wp;
	cap-sd-highspeed;
	cap-sdio-irq;
	keep-power-in-suspend;
	mmc-pwrseq = <&sdio_pwrseq>;
	non-removable;
	pinctrl-names = "default";
	pinctrl-0 = <&sdmmc2m0_bus4 &sdmmc2m0_cmd &sdmmc2m0_clk>;
	sd-uhs-sdr104;
	status = "okay";
};

&pcie2x1 {
	reset-gpios = <&gpio3 RK_PA4 GPIO_ACTIVE_HIGH>;
	status = "okay";

	pcie@0,0 {
		reg = <0x00000000 0 0 0 0>;
		#address-cells = <3>;
		#size-cells = <2>;

		pcie_eth0: pcie-eth@0,0 {
			compatible = "pci10ec,8125";
			reg = <0x000000 0 0 0 0>;

			realtek,led-data = <0 0 0x200 0x02B>;
			realtek,led-feature = /bits/ 8 <0xC0>;
		};
	};
};

&pcie3x1 {
	reset-gpios = <&gpio3 RK_PA1 GPIO_ACTIVE_HIGH>;
	vpcie3v3-supply = <&vcc3v3_nvme>;
	status = "okay";

};

&pcie3x2 {
	reset-gpios = <&gpio2 RK_PD6 GPIO_ACTIVE_HIGH>;
	vpcie3v3-supply = <&vcc3v3_nvme>;
	status = "okay";
};

&usb_host0_xhci {
	status = "okay";
};

&pinctrl {
	nvme {
		vcc3v3_nvme_en: vcc3v3-nvme-en {
			rockchip,pins = <0 RK_PA5 RK_FUNC_GPIO &pcfg_pull_none>;
		};
	};
	oled {
		oled_en: oled-en {
			rockchip,pins = <3 RK_PB0 RK_FUNC_GPIO &pcfg_output_high>;
		};
	};
	bluetooth {
		bt_shutdown_gpio: bt-shutdown-gpio {
			rockchip,pins = <4 RK_PC4 RK_FUNC_GPIO &pcfg_pull_none>;
		};
		bt_host_wake_gpio: bt-host-wake-gpio {
			rockchip,pins = <0 RK_PD4 RK_FUNC_GPIO &pcfg_pull_down>;
		};
		bt_device_wake_gpio: bt-device-wake-gpio {
			rockchip,pins = <0 RK_PD5 RK_FUNC_GPIO &pcfg_pull_none>;
		};
	};
};

&led_green {
	gpios = <&gpio3 RK_PA3 GPIO_ACTIVE_HIGH>;
};

&led_green_en {
	rockchip,pins = <3 RK_PA3 RK_FUNC_GPIO &pcfg_pull_none>;
};

&i2c3 {
	pinctrl-0 = <&i2c3m1_xfer &oled_en>;

	i2c-scl-rising-time-ns = <160>;
	i2c-scl-falling-time-ns = <30>;
	clock-frequency = <400000>;

	status = "okay";
};

&adc_keys {
	vol-up-key {
		label = "recovery";
		linux,code = <KEY_RESTART>;
	};
};

// bluetooth (uart8 = serial@fe6c0000 via GPIO2 pins, alias serial0 -> ttyS0)
&wireless_bluetooth {
	status = "disabled";
};

// IR Receiver
&pwm3 {
	compatible = "rockchip,remotectl-pwm";
	pinctrl-names = "default";
	pinctrl-0 = <&pwm3_pins>;
	remote_pwm_id = <3>;
	handle_cpu_id = <1>;
	remote_support_psci = <0>;
	status = "okay";
};
